AUTOSAR XML (schema 4-2-1)
package /RootP_ASWC_M416
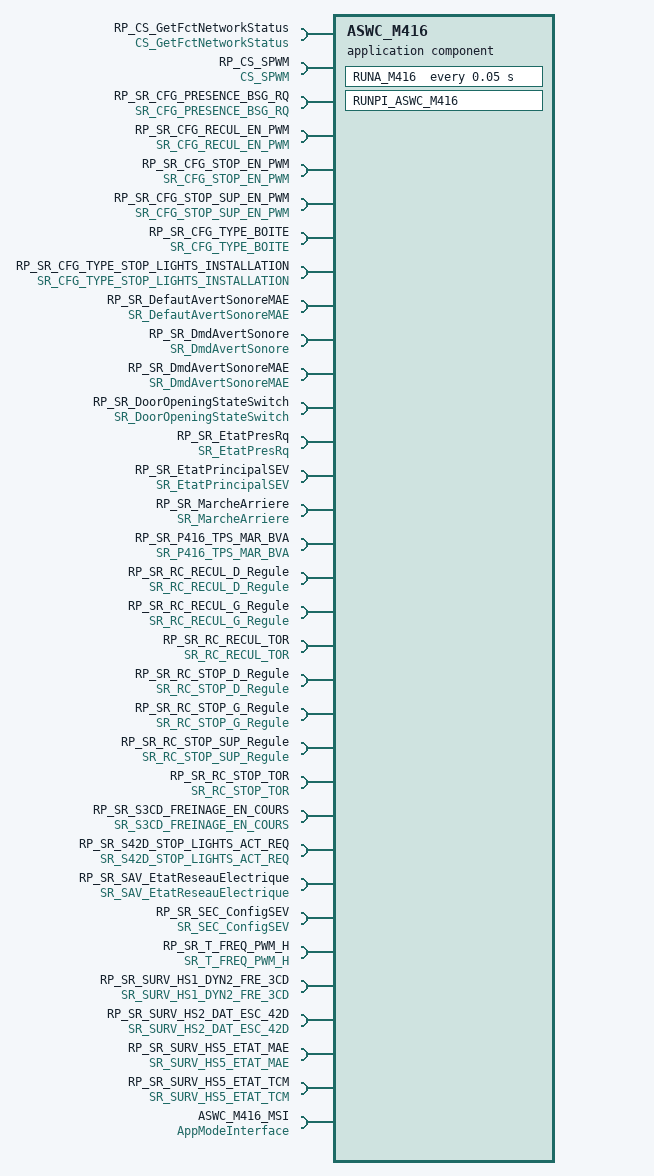
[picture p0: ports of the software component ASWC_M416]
  application sw component type ASWC_M416
    8 x provide/require port:
      PRP_SR_CmdAvertSonore: nonqueued-receiver-com-spec{data-element=CmdAvertSonore, enable-update=0, handle-data-status=1, handle-never-received=0, init-value=CONST_tLOG_0:0}, provided-required-interface=SR_CmdAvertSonore
      PRP_SR_CmdCHMSFxStop: nonqueued-receiver-com-spec{data-element=CmdCHMSFxStop, enable-update=0, handle-data-status=1, handle-never-received=0, init-value=CONST_tLOG_0:0}, provided-required-interface=SR_CmdCHMSFxStop
      PRP_SR_CmdFenderFxStop: nonqueued-receiver-com-spec{data-element=CmdFenderFxStop, enable-update=0, handle-data-status=1, handle-never-received=0, init-value=CONST_tLOG_0:0}, provided-required-interface=SR_CmdFenderFxStop
      PRP_SR_CmdMainReverseLight: nonqueued-receiver-com-spec{data-element=CmdMainReverseLight, enable-update=0, handle-data-status=1, handle-never-received=0, init-value=CONST_tLOG_0:0}, provided-required-interface=SR_CmdMainReverseLight
      PRP_SR_CmdSubstituteFxStop: nonqueued-receiver-com-spec{data-element=CmdSubstituteFxStop, enable-update=0, handle-data-status=1, handle-never-received=0, init-value=CONST_tLOG_0:0}, provided-required-interface=SR_CmdSubstituteFxStop
      PRP_SR_CmdTrailerFxStop: nonqueued-receiver-com-spec{data-element=CmdTrailerFxStop, enable-update=0, handle-data-status=1, handle-never-received=0, init-value=CONST_tLOG_0:0}, provided-required-interface=SR_CmdTrailerFxStop
      PRP_SR_CmdTrailerReverseLight: nonqueued-receiver-com-spec{data-element=CmdTrailerReverseLight, enable-update=0, handle-data-status=1, handle-never-received=0, init-value=CONST_tLOG_0:0}, provided-required-interface=SR_CmdTrailerReverseLight
      PRP_SR_CmdTrunkFxStop: nonqueued-receiver-com-spec{data-element=CmdTrunkFxStop, enable-update=0, handle-data-status=1, handle-never-received=0, init-value=CONST_tLOG_0:0}, provided-required-interface=SR_CmdTrunkFxStop
    33 x require port:
      RP_CS_GetFctNetworkStatus: required-interface=CS_GetFctNetworkStatus
      RP_CS_SPWM: required-interface=CS_SPWM
      RP_SR_CFG_PRESENCE_BSG_RQ: nonqueued-receiver-com-spec{data-element=CFG_PRESENCE_BSG_RQ, enable-update=0, handle-data-status=1, handle-never-received=0, init-value=CONST_tLOG_0:0}, required-interface=SR_CFG_PRESENCE_BSG_RQ
      RP_SR_CFG_RECUL_EN_PWM: nonqueued-receiver-com-spec{data-element=CFG_RECUL_EN_PWM, enable-update=0, handle-data-status=1, handle-never-received=0, init-value=CONST_tBYTE_1:1}, required-interface=SR_CFG_RECUL_EN_PWM
      RP_SR_CFG_STOP_EN_PWM: nonqueued-receiver-com-spec{data-element=CFG_STOP_EN_PWM, enable-update=0, handle-data-status=1, handle-never-received=0, init-value=CONST_tBYTE_1:1}, required-interface=SR_CFG_STOP_EN_PWM
      RP_SR_CFG_STOP_SUP_EN_PWM: nonqueued-receiver-com-spec{data-element=CFG_STOP_SUP_EN_PWM, enable-update=0, handle-data-status=1, handle-never-received=0, init-value=CONST_tBYTE_1:1}, required-interface=SR_CFG_STOP_SUP_EN_PWM
      RP_SR_CFG_TYPE_BOITE: nonqueued-receiver-com-spec{data-element=CFG_TYPE_BOITE, enable-update=0, handle-data-status=1, handle-never-received=0, init-value=CONST_CFG_TYPE_BOITE_t_cTypeBoite_cTypeBoite_Automatique:1}, required-interface=SR_CFG_TYPE_BOITE
      RP_SR_CFG_TYPE_STOP_LIGHTS_INSTALLATION: nonqueued-receiver-com-spec{data-element=CFG_TYPE_STOP_LIGHTS_INSTALLATION, enable-update=0, handle-data-status=1, handle-never-received=0, init-value=CONST_t_TypeRearLightInstall_0:0}, required-interface=SR_CFG_TYPE_STOP_LIGHTS_INSTALLATION
      RP_SR_DefautAvertSonoreMAE: nonqueued-receiver-com-spec{data-element=DefautAvertSonoreMAE, enable-update=0, handle-data-status=1, handle-never-received=0, init-value=CONST_tLOG_0:0}, required-interface=SR_DefautAvertSonoreMAE
      RP_SR_DmdAvertSonore: nonqueued-receiver-com-spec{data-element=DmdAvertSonore, enable-update=0, handle-data-status=1, handle-never-received=0, init-value=CONST_tLOG_0:0}, required-interface=SR_DmdAvertSonore
      RP_SR_DmdAvertSonoreMAE: nonqueued-receiver-com-spec{data-element=DmdAvertSonoreMAE, enable-update=0, handle-data-status=1, handle-never-received=0, init-value=CONST_tLOG_0:0}, required-interface=SR_DmdAvertSonoreMAE
      RP_SR_DoorOpeningStateSwitch: nonqueued-receiver-com-spec{data-element=DoorOpeningState, enable-update=0, handle-data-status=1, handle-never-received=0, init-value=CONST_DoorOpeningState_tOpeningPosition_eMVA_None:0}, required-interface=SR_DoorOpeningStateSwitch
      RP_SR_EtatPresRq: nonqueued-receiver-com-spec{data-element=EtatPresRq, enable-update=0, handle-data-status=1, handle-never-received=0, init-value=CONST_tLOG_0:0}, required-interface=SR_EtatPresRq
      RP_SR_EtatPrincipalSEV: nonqueued-receiver-com-spec{data-element=EtatPrincipalSEV, enable-update=0, handle-data-status=1, handle-never-received=0, init-value=CONST_EtatPrincipalSEV_t_SEV_SEV_Arret:105}, required-interface=SR_EtatPrincipalSEV
      RP_SR_MarcheArriere: nonqueued-receiver-com-spec{data-element=MarcheArriere, enable-update=0, handle-data-status=1, handle-never-received=0, init-value=CONST_tLOG_0:0}, required-interface=SR_MarcheArriere
      RP_SR_P416_TPS_MAR_BVA: nonqueued-receiver-com-spec{data-element=P416_TPS_MAR_BVA, enable-update=0, handle-data-status=1, handle-never-received=0, init-value=CONST_tBYTE_10:10}, required-interface=SR_P416_TPS_MAR_BVA
      RP_SR_RC_RECUL_D_Regule: nonqueued-receiver-com-spec{data-element=RC_RECUL_D_Regule, enable-update=0, handle-data-status=1, handle-never-received=0, init-value=CONST_tWORD_100:100}, required-interface=SR_RC_RECUL_D_Regule
      RP_SR_RC_RECUL_G_Regule: nonqueued-receiver-com-spec{data-element=RC_RECUL_G_Regule, enable-update=0, handle-data-status=1, handle-never-received=0, init-value=CONST_tWORD_100:100}, required-interface=SR_RC_RECUL_G_Regule
      RP_SR_RC_RECUL_TOR: nonqueued-receiver-com-spec{data-element=RC_RECUL_TOR, enable-update=0, handle-data-status=1, handle-never-received=0, init-value=CONST_tWORD_255:255}, required-interface=SR_RC_RECUL_TOR
      RP_SR_RC_STOP_D_Regule: nonqueued-receiver-com-spec{data-element=RC_STOP_D_Regule, enable-update=0, handle-data-status=1, handle-never-received=0, init-value=CONST_tWORD_100:100}, required-interface=SR_RC_STOP_D_Regule
      RP_SR_RC_STOP_G_Regule: nonqueued-receiver-com-spec{data-element=RC_STOP_G_Regule, enable-update=0, handle-data-status=1, handle-never-received=0, init-value=CONST_tWORD_100:100}, required-interface=SR_RC_STOP_G_Regule
      RP_SR_RC_STOP_SUP_Regule: nonqueued-receiver-com-spec{data-element=RC_STOP_SUP_Regule, enable-update=0, handle-data-status=1, handle-never-received=0, init-value=CONST_tWORD_100:100}, required-interface=SR_RC_STOP_SUP_Regule
      RP_SR_RC_STOP_TOR: nonqueued-receiver-com-spec{data-element=RC_STOP_TOR, enable-update=0, handle-data-status=1, handle-never-received=0, init-value=CONST_tWORD_255:255}, required-interface=SR_RC_STOP_TOR
      RP_SR_S3CD_FREINAGE_EN_COURS: nonqueued-receiver-com-spec{data-element=S3CD_FREINAGE_EN_COURS, enable-update=0, handle-data-status=1, handle-never-received=0, init-value=CONST_S3CD_FREINAGE_EN_COURS_t_FreinageEnCours_cNoBraking:0}, required-interface=SR_S3CD_FREINAGE_EN_COURS
      RP_SR_S42D_STOP_LIGHTS_ACT_REQ: nonqueued-receiver-com-spec{data-element=S42D_STOP_LIGHTS_ACT_REQ, enable-update=0, handle-data-status=1, handle-never-received=0, init-value=CONST_tLOG_0:0}, required-interface=SR_S42D_STOP_LIGHTS_ACT_REQ
      RP_SR_SAV_EtatReseauElectrique: nonqueued-receiver-com-spec{data-element=SAV_EtatReseauElectrique, enable-update=0, handle-data-status=1, handle-never-received=0, init-value=CONST_t_cGEE_1_0:0}, required-interface=SR_SAV_EtatReseauElectrique
      RP_SR_SEC_ConfigSEV: nonqueued-receiver-com-spec{data-element=SEC_ConfigSEV, enable-update=0, handle-data-status=1, handle-never-received=0, init-value=CONST_t_cCSEV_4:4}, required-interface=SR_SEC_ConfigSEV
      RP_SR_T_FREQ_PWM_H: nonqueued-receiver-com-spec{data-element=T_FREQ_PWM_H, enable-update=0, handle-data-status=1, handle-never-received=0, init-value=CONST_tWORD_7:7}, required-interface=SR_T_FREQ_PWM_H
      RP_SR_SURV_HS1_DYN2_FRE_3CD: nonqueued-receiver-com-spec{data-element=deSurvHs1Dyn2Fre3cd, alive-timeout=30, enable-update=0, handle-data-status=1, handle-never-received=0, init-value=CONST_tLOG_0:0}, required-interface=SR_SURV_HS1_DYN2_FRE_3CD
      RP_SR_SURV_HS2_DAT_ESC_42D: nonqueued-receiver-com-spec{data-element=deSurvHs2DatEsc42d, alive-timeout=150, enable-update=0, handle-data-status=1, handle-never-received=0, init-value=CONST_tLOG_0:0}, required-interface=SR_SURV_HS2_DAT_ESC_42D
      RP_SR_SURV_HS5_ETAT_MAE: nonqueued-receiver-com-spec{data-element=deSurvHs5EtatMae, alive-timeout=600, enable-update=0, handle-data-status=1, handle-never-received=0, init-value=CONST_tLOG_0:0}, required-interface=SR_SURV_HS5_ETAT_MAE
      RP_SR_SURV_HS5_ETAT_TCM: nonqueued-receiver-com-spec{data-element=deSurvHs5EtatTcm, alive-timeout=300, enable-update=0, handle-data-status=1, handle-never-received=0, init-value=CONST_tLOG_0:0}, required-interface=SR_SURV_HS5_ETAT_TCM
      ASWC_M416_MSI: required-interface=AppModeInterface
    behavior IB_ASWC_M416: data-type-mapping=ApplicationModeMapping, handle-termination-and-restart=NO-SUPPORT
      ar-typed-per-instance-memorys:
        5 x data:
          PIM_M416_CmdCHMSFxStop_Prec: type=tLOG, init-value=CONST_tLOG_0:0
          PIM_M416_CmdFenderStop_Prec: type=tLOG, init-value=CONST_tLOG_0:0
          PIM_M416_CmdMainReverse_Prec: type=tLOG, init-value=CONST_tLOG_0:0
          PIM_M416_CounterPrec: type=tBYTE, init-value=CONST_tBYTE_0:0
          PIM_M416_EtatVHL_Prec: type=tLOG, init-value=CONST_tLOG_0:0
      timing event RUNA_M416_Cyclic: start-on-event=RUNA_M416, period=0.05
        disabled-mode:
          ASWC_M416_MSI.AppMode.APP_WAKEUP
          ASWC_M416_MSI.AppMode.APP_OFF
          ASWC_M416_MSI.AppMode.APP_SYNC_INIT
          ASWC_M416_MSI.AppMode.APP_CONFIG
      swc mode switch event RUNPI_ASWC_M416_ENTRY: start-on-event=RUNPI_ASWC_M416, activation=ON-ENTRY, mode=ASWC_M416_MSI.AppMode.APP_WAKEUP
      runnable RUNA_M416
        data-read-access:
          38 x access:
            dra_RP_SR_DefautAvertSonoreMAE_DefautAvertSonoreMAE: accessed-variable=RP_SR_DefautAvertSonoreMAE.DefautAvertSonoreMAE
            dra_RP_SR_DmdAvertSonore_DmdAvertSonore: accessed-variable=RP_SR_DmdAvertSonore.DmdAvertSonore
            dra_RP_SR_DmdAvertSonoreMAE_DmdAvertSonoreMAE: accessed-variable=RP_SR_DmdAvertSonoreMAE.DmdAvertSonoreMAE
            dra_RP_SR_DoorOpeningStateSwitch_DoorOpeningState: accessed-variable=RP_SR_DoorOpeningStateSwitch.DoorOpeningState
            dra_RP_SR_EtatPresRq_EtatPresRq: accessed-variable=RP_SR_EtatPresRq.EtatPresRq
            dra_RP_SR_EtatPrincipalSEV_EtatPrincipalSEV: accessed-variable=RP_SR_EtatPrincipalSEV.EtatPrincipalSEV
            dra_RP_SR_MarcheArriere_MarcheArriere: accessed-variable=RP_SR_MarcheArriere.MarcheArriere
            dra_RP_SR_S3CD_FREINAGE_EN_COURS_S3CD_FREINAGE_EN_COURS: accessed-variable=RP_SR_S3CD_FREINAGE_EN_COURS.S3CD_FREINAGE_EN_COURS
            dra_RP_SR_S42D_STOP_LIGHTS_ACT_REQ_S42D_STOP_LIGHTS_ACT_REQ: accessed-variable=RP_SR_S42D_STOP_LIGHTS_ACT_REQ.S42D_STOP_LIGHTS_ACT_REQ
            dra_RP_SR_SAV_EtatReseauElectrique_SAV_EtatReseauElectrique: accessed-variable=RP_SR_SAV_EtatReseauElectrique.SAV_EtatReseauElectrique
            dra_RP_SR_SEC_ConfigSEV_SEC_ConfigSEV: accessed-variable=RP_SR_SEC_ConfigSEV.SEC_ConfigSEV
            dra_RP_SR_SURV_HS1_DYN2_FRE_3CD_deSurvHs1Dyn2Fre3cd: accessed-variable=RP_SR_SURV_HS1_DYN2_FRE_3CD.deSurvHs1Dyn2Fre3cd
            dra_RP_SR_SURV_HS2_DAT_ESC_42D_deSurvHs2DatEsc42d: accessed-variable=RP_SR_SURV_HS2_DAT_ESC_42D.deSurvHs2DatEsc42d
            dra_RP_SR_SURV_HS5_ETAT_MAE_deSurvHs5EtatMae: accessed-variable=RP_SR_SURV_HS5_ETAT_MAE.deSurvHs5EtatMae
            dra_RP_SR_SURV_HS5_ETAT_TCM_deSurvHs5EtatTcm: accessed-variable=RP_SR_SURV_HS5_ETAT_TCM.deSurvHs5EtatTcm
            dra_RP_SR_CFG_PRESENCE_BSG_RQ_CFG_PRESENCE_BSG_RQ: accessed-variable=RP_SR_CFG_PRESENCE_BSG_RQ.CFG_PRESENCE_BSG_RQ
            dra_RP_SR_CFG_RECUL_EN_PWM_CFG_RECUL_EN_PWM: accessed-variable=RP_SR_CFG_RECUL_EN_PWM.CFG_RECUL_EN_PWM
            dra_RP_SR_CFG_STOP_EN_PWM_CFG_STOP_EN_PWM: accessed-variable=RP_SR_CFG_STOP_EN_PWM.CFG_STOP_EN_PWM
            dra_RP_SR_CFG_STOP_SUP_EN_PWM_CFG_STOP_SUP_EN_PWM: accessed-variable=RP_SR_CFG_STOP_SUP_EN_PWM.CFG_STOP_SUP_EN_PWM
            dra_RP_SR_CFG_TYPE_BOITE_CFG_TYPE_BOITE: accessed-variable=RP_SR_CFG_TYPE_BOITE.CFG_TYPE_BOITE
            dra_RP_SR_CFG_TYPE_STOP_LIGHTS_INSTALLATION_CFG_TYPE_STOP_LIGHTS_INSTALLATION: accessed-variable=RP_SR_CFG_TYPE_STOP_LIGHTS_INSTALLATION.CFG_TYPE_STOP_LIGHTS_INSTALLATION
            dra_RP_SR_P416_TPS_MAR_BVA_P416_TPS_MAR_BVA: accessed-variable=RP_SR_P416_TPS_MAR_BVA.P416_TPS_MAR_BVA
            dra_RP_SR_RC_RECUL_D_Regule_RC_RECUL_D_Regule: accessed-variable=RP_SR_RC_RECUL_D_Regule.RC_RECUL_D_Regule
            dra_RP_SR_RC_RECUL_G_Regule_RC_RECUL_G_Regule: accessed-variable=RP_SR_RC_RECUL_G_Regule.RC_RECUL_G_Regule
            dra_RP_SR_RC_RECUL_TOR_RC_RECUL_TOR: accessed-variable=RP_SR_RC_RECUL_TOR.RC_RECUL_TOR
            dra_RP_SR_RC_STOP_D_Regule_RC_STOP_D_Regule: accessed-variable=RP_SR_RC_STOP_D_Regule.RC_STOP_D_Regule
            dra_RP_SR_RC_STOP_G_Regule_RC_STOP_G_Regule: accessed-variable=RP_SR_RC_STOP_G_Regule.RC_STOP_G_Regule
            dra_RP_SR_RC_STOP_SUP_Regule_RC_STOP_SUP_Regule: accessed-variable=RP_SR_RC_STOP_SUP_Regule.RC_STOP_SUP_Regule
            dra_RP_SR_RC_STOP_TOR_RC_STOP_TOR: accessed-variable=RP_SR_RC_STOP_TOR.RC_STOP_TOR
            dra_RP_SR_T_FREQ_PWM_H_T_FREQ_PWM_H: accessed-variable=RP_SR_T_FREQ_PWM_H.T_FREQ_PWM_H
            dra_PRP_SR_CmdAvertSonore_CmdAvertSonore: accessed-variable=PRP_SR_CmdAvertSonore.CmdAvertSonore
            dra_PRP_SR_CmdCHMSFxStop_CmdCHMSFxStop: accessed-variable=PRP_SR_CmdCHMSFxStop.CmdCHMSFxStop
            dra_PRP_SR_CmdFenderFxStop_CmdFenderFxStop: accessed-variable=PRP_SR_CmdFenderFxStop.CmdFenderFxStop
            dra_PRP_SR_CmdMainReverseLight_CmdMainReverseLight: accessed-variable=PRP_SR_CmdMainReverseLight.CmdMainReverseLight
            dra_PRP_SR_CmdSubstituteFxStop_CmdSubstituteFxStop: accessed-variable=PRP_SR_CmdSubstituteFxStop.CmdSubstituteFxStop
            dra_PRP_SR_CmdTrailerFxStop_CmdTrailerFxStop: accessed-variable=PRP_SR_CmdTrailerFxStop.CmdTrailerFxStop
            dra_PRP_SR_CmdTrailerReverseLight_CmdTrailerReverseLight: accessed-variable=PRP_SR_CmdTrailerReverseLight.CmdTrailerReverseLight
            dra_PRP_SR_CmdTrunkFxStop_CmdTrunkFxStop: accessed-variable=PRP_SR_CmdTrunkFxStop.CmdTrunkFxStop
        data-write-access:
          8 x access:
            dwa_PRP_SR_CmdAvertSonore_CmdAvertSonore: accessed-variable=PRP_SR_CmdAvertSonore.CmdAvertSonore
            dwa_PRP_SR_CmdCHMSFxStop_CmdCHMSFxStop: accessed-variable=PRP_SR_CmdCHMSFxStop.CmdCHMSFxStop
            dwa_PRP_SR_CmdFenderFxStop_CmdFenderFxStop: accessed-variable=PRP_SR_CmdFenderFxStop.CmdFenderFxStop
            dwa_PRP_SR_CmdMainReverseLight_CmdMainReverseLight: accessed-variable=PRP_SR_CmdMainReverseLight.CmdMainReverseLight
            dwa_PRP_SR_CmdSubstituteFxStop_CmdSubstituteFxStop: accessed-variable=PRP_SR_CmdSubstituteFxStop.CmdSubstituteFxStop
            dwa_PRP_SR_CmdTrailerFxStop_CmdTrailerFxStop: accessed-variable=PRP_SR_CmdTrailerFxStop.CmdTrailerFxStop
            dwa_PRP_SR_CmdTrailerReverseLight_CmdTrailerReverseLight: accessed-variable=PRP_SR_CmdTrailerReverseLight.CmdTrailerReverseLight
            dwa_PRP_SR_CmdTrunkFxStop_CmdTrunkFxStop: accessed-variable=PRP_SR_CmdTrunkFxStop.CmdTrunkFxStop
        sync call sscp_RUNA_M416_CS_GetFctNetworkStatus_Get: operation=RP_CS_GetFctNetworkStatus.Get, timeout=0
        sync call sscp_RUNA_M416_CS_SPWM_Set: operation=RP_CS_SPWM.Set, timeout=0
      runnable RUNPI_ASWC_M416
package /RootP_Implementatation
  swc implementation Implementatation_ASWC_M416: programming-language=C, sw-version=1.0.0, vendor-id=1, behavior=IB_ASWC_M416
    code-descriptors:
      code SRC: artifact-descriptors=autosar-engineering-object={short-label=EngObject, category=SWSRC}
    resource consumption Resources
